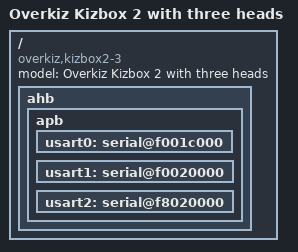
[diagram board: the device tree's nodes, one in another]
/*
 * at91-kizbox2-3.dts - Device Tree file for Overkiz Kizbox 2 board with three heads
 *
 * Copyright (C) 2015 Antoine AUBERT <a.aubert@overkiz.com>
 *                    Kévin RAYMOND <k.raymond@overkiz.com>
 *
 * Licensed under GPLv2 or later.
 */
/dts-v1/;
#include "at91-kizbox2_common.dtsi"

/ {
	model = "Overkiz Kizbox 2 with three heads";
	compatible = "overkiz,kizbox2-3", "atmel,sama5d31", "atmel,sama5d3", "atmel,sama5";

	ahb {
		apb {
			usart0: serial@f001c000 {
				status = "okay";
			};

			usart1: serial@f0020000 {
				status = "okay";
			};

			usart2: serial@f8020000 {
				status = "okay";
			};
		};
	};
};
